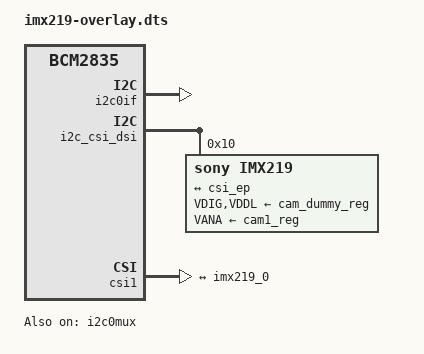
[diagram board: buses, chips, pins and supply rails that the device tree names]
// SPDX-License-Identifier: GPL-2.0-only
// Definitions for IMX219 camera module on VC I2C bus
/dts-v1/;
/plugin/;

#include <dt-bindings/gpio/gpio.h>

/{
	compatible = "brcm,bcm2835";

	fragment@0 {
		target = <&i2c0if>;
		__overlay__ {
			status = "okay";
		};
	};

	frag1: fragment@1 {
		target = <&cam1_clk>;
		__overlay__ {
			status = "okay";
			clock-frequency = <24000000>;
		};
	};

	fragment@2 {
		target = <&i2c0mux>;
		__overlay__ {
			status = "okay";
		};
	};

	fragment@3 {
		target = <&csi>;
		__overlay__ {
			brcm,media-controller;
		};
	};

	frag100: fragment@100 {
		target = <&i2c_csi_dsi>;
		i2c_bus: __overlay__ {
			status = "okay";
		};
	};

	frag101: fragment@101 {
		target = <&csi1>;
		csi: __overlay__ {
			status = "okay";
		};
	};

	frag102: fragment@102 {
		target = <&imx219>;
		__overlay__ {
			clocks = <&cam1_clk>;
			VANA-supply = <&cam1_reg>;	/* 2.8v */
		};
	};

	frag103: fragment@103 {
		target = <&imx219>;
		__dormant__ {
			clocks = <&cam0_clk>;
			VANA-supply = <&cam0_reg>;	/* 2.8v */
		};
	};

	fragment@200 {
		target = <&i2c_bus>;
		__overlay__ {
			#address-cells = <1>;
			#size-cells = <0>;
			status = "okay";

			imx219: imx219@10 {
				compatible = "sony,imx219";
				reg = <0x10>;
				status = "okay";

				clock-names = "xclk";

				VDIG-supply = <&cam_dummy_reg>;	/* 1.8v */
				VDDL-supply = <&cam_dummy_reg>;	/* 1.2v */

				rotation = <180>;
				orientation = <2>;

				port {
					imx219_0: endpoint {
						remote-endpoint = <&csi_ep>;
						clock-lanes = <0>;
						data-lanes = <1 2>;
						clock-noncontinuous;
						link-frequencies =
							/bits/ 64 <456000000>;
					};
				};
			};
		};
	};

	fragment@201 {
		target = <&csi>;
		__overlay__ {
			status = "okay";

			port {
				csi_ep: endpoint {
					remote-endpoint = <&imx219_0>;
					clock-lanes = <0>;
					data-lanes = <1 2>;
					clock-noncontinuous;
				};
			};
		};
	};

	__overrides__ {
		rotation = <&imx219>,"rotation:0";
		orientation = <&imx219>,"orientation:0";
		media-controller = <0>,"=5";
		cam0 = <&frag100>, "target:0=",<&i2c_vc>,
		       <&frag101>, "target:0=",<&csi0>,
		       <&frag1>, "target:0=",<&cam0_clk>,
		       <0>, "-102+103";
	};
};
